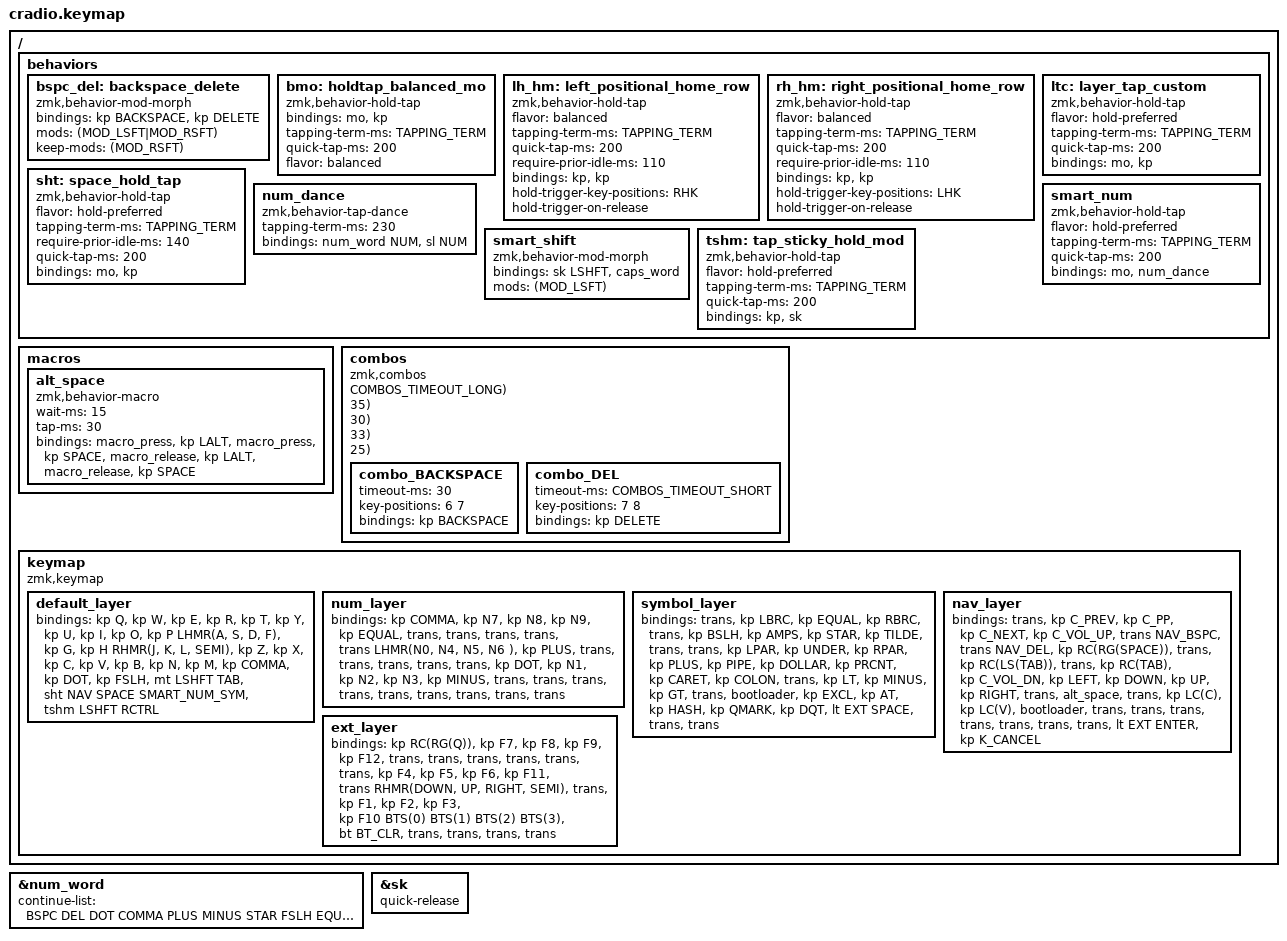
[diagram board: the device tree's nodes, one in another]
/*
 * Copyright (c) 2020 The ZMK Contributors
 *
 * SPDX-License-Identifier: MIT
 */

#include <behaviors.dtsi>
#include <behaviors/num_word.dtsi>
#include <dt-bindings/zmk/keys.h>
#include <dt-bindings/zmk/bt.h>

#define DEF 0
#define NUM 1
#define SYM 2
#define NAV 3
#define EXT 4

// left hand keys with thumb cluster
#define LHK 0 1 2 3 4    10 11 12 13 14  20 21 22 23 24   30 31   32 33
// right hand keys with thum cluster
#define RHK 5 6 7 8 9    15 16 17 18 19  25 26 27 28 29   30 31   32 33

#define LHMR(K1,K2,K3,K4) &lh_hm LGUI K1    &lh_hm LALT K2   &lh_hm LCTRL K3   &lh_hm LSHFT K4
#define RHMR(K1,K2,K3,K4) &rh_hm LSHFT K1    &rh_hm LCTRL K2   &rh_hm LALT K3   &rh_hm LGUI K4

#define NAV_BSPC  &mt LC(BSPC) BSPC  // Tap: bspc  | Long-tap: delete word bwd.
#define NAV_DEL   &mt LC(DEL)  DEL   // Tap: del   | Long-tap: delete word fwd.


#define BTS(num) &bt BT_SEL num

#define TAPPING_TERM 220

/ {
    behaviors {
        bspc_del: backspace_delete {
            compatible = "zmk,behavior-mod-morph";
            #binding-cells = <0>;
            bindings = <&kp BACKSPACE>, <&kp DELETE>;
            mods = <(MOD_LSFT|MOD_RSFT)>;
            keep-mods = <(MOD_RSFT)>;
        };
        bmo: holdtap_balanced_mo {
            compatible = "zmk,behavior-hold-tap";
            #binding-cells = <2>;
            bindings = <&mo>, <&kp>;
            tapping-term-ms = <TAPPING_TERM>;
            quick-tap-ms = <200>;
            flavor = "balanced";
        };
        lh_hm: left_positional_home_row {
            compatible = "zmk,behavior-hold-tap";
            #binding-cells = <2>;
            flavor = "balanced";
            tapping-term-ms = <TAPPING_TERM>;
            quick-tap-ms = <200>;
            require-prior-idle-ms = <110>;
            bindings = <&kp>, <&kp>;
            hold-trigger-key-positions = <RHK>;    // <---[[right-hand keys]]
            hold-trigger-on-release;
        };
        rh_hm: right_positional_home_row {
            compatible = "zmk,behavior-hold-tap";
            #binding-cells = <2>;
            flavor = "balanced";
            tapping-term-ms = <TAPPING_TERM>;
            quick-tap-ms = <200>;
            require-prior-idle-ms = <110>;
            bindings = <&kp>, <&kp>;
            hold-trigger-key-positions = <LHK>;    // <---[[left-hand keys]]
            hold-trigger-on-release;
        };
        ltc: layer_tap_custom {
            compatible = "zmk,behavior-hold-tap";
            #binding-cells = <2>;
            flavor = "hold-preferred";
            tapping-term-ms = <TAPPING_TERM>;
            quick-tap-ms = <200>;
            bindings = <&mo>, <&kp>;
        };
        sht: space_hold_tap {
            compatible = "zmk,behavior-hold-tap";
            #binding-cells = <2>;
            flavor = "hold-preferred";
            tapping-term-ms = <TAPPING_TERM>;
            require-prior-idle-ms = <140>;
            quick-tap-ms = <200>;
            bindings = <&mo>, <&kp>;
        };
        // num-word
        num_dance: num_dance {
            compatible = "zmk,behavior-tap-dance";
            #binding-cells = <0>;
            tapping-term-ms = <230>;
            bindings = <&num_word NUM>, <&sl NUM>;
        };
        smart_num: smart_num { // num-word on tap, &mo on hold, sl on double tap
            compatible = "zmk,behavior-hold-tap";
            #binding-cells = <2>;
            flavor = "hold-preferred";
            tapping-term-ms = <TAPPING_TERM>;
            quick-tap-ms = <200>;
            bindings = <&mo>, <&num_dance>;
        };
        smart_shift: smart_shift {
            compatible = "zmk,behavior-mod-morph";
            #binding-cells = <0>;
            bindings = <&sk LSHFT>, <&caps_word>;
            mods = <(MOD_LSFT)>;
        };
        tshm: tap_sticky_hold_mod {
            compatible = "zmk,behavior-hold-tap";
            #binding-cells = <2>; /* Важно: параметров два */
            flavor = "hold-preferred"; /* Удержание имеет приоритет */
            tapping-term-ms = <TAPPING_TERM>;   /* Время, после которого нажатие считается удержанием */
            quick-tap-ms = <200>;      /* (Опционально) Для более отзывчивого тапа */
            bindings = <&kp>, <&sk>;   /* Удержание: обычный keypress, тап: sticky-key */
        };
    };
};


// workaround for macos issue with switching input source
/ {
  macros {
    alt_space: alt_space {
      compatible = "zmk,behavior-macro";
      #binding-cells = <0>;
      wait-ms = <15>;
      tap-ms  = <30>;
      bindings
        = <&macro_press   &kp LALT>
        , <&macro_press     &kp SPACE>
        , <&macro_release &kp LALT>
        , <&macro_release &kp SPACE>
        ;
    };
  };
};

&num_word {  // num-word, requires PR #1451( used urob fork )
    // layers = <NUM>;
    continue-list = <BSPC DEL DOT COMMA PLUS MINUS STAR FSLH EQUAL SPACE>;
};
&sk {  // sticky-key config
    quick-release; // no double capitalization when rolling keys
};



#define NEXT_DESKTOP &kp LG(LC(RIGHT))
#define PREV_DESKTOP &kp LG(LC(LEFT))
#define SMART_NUM_SYM &smart_num SYM 0

#define COMBOS_TIMEOUT_SHORT 20
#define COMBOS_TIMEOUT_MEDIUM 25
#define COMBOS_TIMEOUT_LONG 60
#define MK_COMBO(NAME,KEYS,RESULT,TIMEOUT) NAME {\
    timeout-ms = <TIMEOUT>;\
    key-positions = <KEYS>;\
    bindings = <RESULT>;\
}


/ {
    combos {
        compatible = "zmk,combos";
        combo_BACKSPACE {
            timeout-ms = <30>;
            key-positions = <6 7>;
            bindings = <&kp BACKSPACE>;
        };
        combo_DEL {
            timeout-ms = <COMBOS_TIMEOUT_SHORT>;
            key-positions = <7 8>;
            bindings = <&kp DELETE>;
        };

        MK_COMBO(combo_1,0 10,&kp N1, COMBOS_TIMEOUT_LONG);
        MK_COMBO(combo_2,1 11,&kp N2, COMBOS_TIMEOUT_LONG);
        MK_COMBO(combo_3,2 12,&kp N3, COMBOS_TIMEOUT_LONG);
        MK_COMBO(combo_4,3 13,&kp N4, COMBOS_TIMEOUT_LONG);
        MK_COMBO(combo_5,4 14,&kp N5, COMBOS_TIMEOUT_LONG);
        MK_COMBO(combo_6,5 15,&kp N6, COMBOS_TIMEOUT_LONG);
        MK_COMBO(combo_7,6 16,&kp N7, COMBOS_TIMEOUT_LONG);
        MK_COMBO(combo_8,7 17,&kp N8, COMBOS_TIMEOUT_LONG);
        MK_COMBO(combo_9,8 18,&kp N9, COMBOS_TIMEOUT_LONG);
        MK_COMBO(combo_0,9 19,&kp N0, COMBOS_TIMEOUT_LONG);

        MK_COMBO(combo_GRAVE,0 1,&kp GRAVE, 35); // ё
        MK_COMBO(combo_SQT,17 18,&kp SQT, 30); // э
        MK_COMBO(combo_LBKT,22 23,&kp LBKT, 33); // х
        MK_COMBO(combo_RBKT,26 27,&kp RBKT, 33); // ъ
        MK_COMBO(combo_ESC,16 17,&kp ESC, 25);
        //MK_COMBO(combo_TAB,15 16,&kp TAB, 25);
        MK_COMBO(combo_ENTER,12 13,&kp ENTER, 25);
    };
};

/ {
        keymap {
                compatible = "zmk,keymap";

                default_layer {
                        bindings = <
// .---------------------------------------------------------------------------------------------------------------------------------------.
// |          |          |          |          |          |          | | |          |          |          |          |          |          |
                 &kp Q     &kp W      &kp E      &kp R      &kp T          &kp Y      &kp U      &kp I       &kp O      &kp P           
// |          |          |          |          |          |          | | |          |          |          |          |          |          |
                 LHMR(A,       S,        D,          F)      &kp G          &kp H      RHMR(J,       K,         L,         SEMI)         
// |          |          |          |          |          |          | | |          |          |          |          |          |          |
                 &kp Z      &kp X      &kp C      &kp V      &kp B          &kp N      &kp M      &kp COMMA   &kp DOT   &kp FSLH          
// |          |          |          |          |          |          | | |          |          |          |          |          |          |
// '---------------------------------------------------------------------------------------------------------------------------------------'
//                         |             |             |             | | |             |             |             |
                                        &mt LSHFT TAB  &sht NAV SPACE     SMART_NUM_SYM  &tshm LSHFT RCTRL
//                         |             |             |             | | |             |             |             |
//                         '---------------------------------------------------------------------------------------'
                        >;
                };
                num_layer {
                        bindings = <
// .---------------------------------------------------------------------------------------------------------------------------------------.
// |          |          |          |          |          |          | | |          |          |          |          |          |          |
              &kp COMMA   &kp N7      &kp N8     &kp N9    &kp EQUAL        &trans     &trans     &trans     &trans    &trans
// |          |          |          |          |          |          | | |          |          |          |          |          |          |
              LHMR(N0,        N4,          N5,       N6 )      &kp PLUS        &trans     &trans     &trans     &trans    &trans
// |          |          |          |          |          |          | | |          |          |          |          |          |          |
              &kp DOT      &kp N1      &kp N2    &kp N3    &kp MINUS        &trans     &trans     &trans     &trans    &trans
// |          |          |          |          |          |          | | |          |          |          |          |          |          |
// '---------------------------------------------------------------------------------------------------------------------------------------'
//                         |             |             |             | | |             |             |             |
                                              &trans         &trans           &trans         &trans
//                         |             |             |             | | |             |             |             |
//                         '---------------------------------------------------------------------------------------'
                        >;
                };

                symbol_layer {
                        bindings = <
// .---------------------------------------------------------------------------------------------------------------------------------------.
// |          |          |          |          |          |          | | |          |          |          |          |          |          |
               &trans     &kp LBRC  &kp EQUAL   &kp RBRC    &trans         &kp BSLH     &kp AMPS  &kp STAR  &kp TILDE     &trans    
// |          |          |          |          |          |          | | |          |          |          |          |          |          |
              &trans     &kp LPAR   &kp UNDER   &kp RPAR   &kp PLUS       &kp PIPE  &kp DOLLAR  &kp PRCNT  &kp CARET  &kp COLON  
// |          |          |          |          |          |          | | |          |          |          |          |          |          |
               &trans      &kp LT    &kp MINUS     &kp GT    &trans      &bootloader  &kp EXCL   &kp AT     &kp HASH  &kp QMARK    
// |          |          |          |          |          |          | | |          |          |          |          |          |          |
// '---------------------------------------------------------------------------------------------------------------------------------------'
//                         |             |             |             | | |             |             |             |
                                            &kp DQT     &lt EXT SPACE           &trans      &trans
//                         |             |             |             | | |             |             |             |
//                         '---------------------------------------------------------------------------------------'
                        >;
                };

                nav_layer {
                        bindings = <
// .---------------------------------------------------------------------------------------------------------------------------------------.
// |          |          |          |          |          |          | | |          |          |          |          |          |          |
                 &trans  &kp C_PREV  &kp C_PP &kp C_NEXT &kp C_VOL_UP     &trans     NAV_BSPC    &trans     NAV_DEL  &kp RC(RG(SPACE))
// |          |          |          |          |          |          | | |          |          |          |          |          |          |
                         /*RC for mac*/
               &trans  &kp RC(LS(TAB)) &trans  &kp RC(TAB) &kp C_VOL_DN    &kp LEFT   &kp DOWN   &kp UP     &kp RIGHT  &trans
// |          |          |          |          |          |          | | |          |          |          |          |          |          |
                &alt_space  &trans   &kp LC(C)   &kp LC(V)  &bootloader    &trans       &trans      &trans     &trans    &trans
// |          |          |          |          |          |          | | |          |          |          |          |          |          |
// '---------------------------------------------------------------------------------------------------------------------------------------'
//                         |             |             |             | | |             |             |             |
                                           &trans         &trans          &lt EXT ENTER  &kp K_CANCEL
//                         |             |             |             | | |             |             |             |
//                         '---------------------------------------------------------------------------------------'
                        >;
                };

                ext_layer {
                        bindings = <
// .---------------------------------------------------------------------------------------------------------------------------------------.
// |          |          |          |          |          |          | | |          |          |          |          |          |          |
           &kp RC(RG(Q))   &kp F7     &kp F8     &kp F9   &kp F12         &trans    &trans     &trans     &trans      &trans
// |          |          |          |          |          |          | | |          |          |          |          |          |          |
              &trans       &kp F4      &kp F5     &kp F6    &kp F11         &trans    RHMR(DOWN,    UP,       RIGHT,    SEMI)
// |          |          |          |          |          |          | | |          |          |          |          |          |          |
                &trans     &kp F1     &kp F2     &kp F3     &kp F10        BTS(0)      BTS(1)     BTS(2)    BTS(3)   &bt BT_CLR
// |          |          |          |          |          |          | | |          |          |          |          |          |          |
// '---------------------------------------------------------------------------------------------------------------------------------------'
//                         |             |             |             | | |             |             |             |
                                             &trans         &trans           &trans         &trans
//                         |             |             |             | | |             |             |             |
//                         '---------------------------------------------------------------------------------------'
                        >;
                };
        };
};
